# dm648_cslr_mcasp_001 register map
Vendor: Texas Instruments
Peripheral module from a debugger description file.
Registers are 32-bit, access not given, reset 0x0 unless marked. A register's access mark holds for its fields unless they carry their own. Offsets are as the file gives them; lines under a group give offsets from that group; [hi:lo] are bit positions; {n}, {i} and the like mark numbered series; 'fields as' and 'values as' point back to an identical list; <NAME> marks a mode.

## MCASP — This module provides an interface to program the MCASP (Multichannel Audio serial port) registers. These registers are memory mapped.
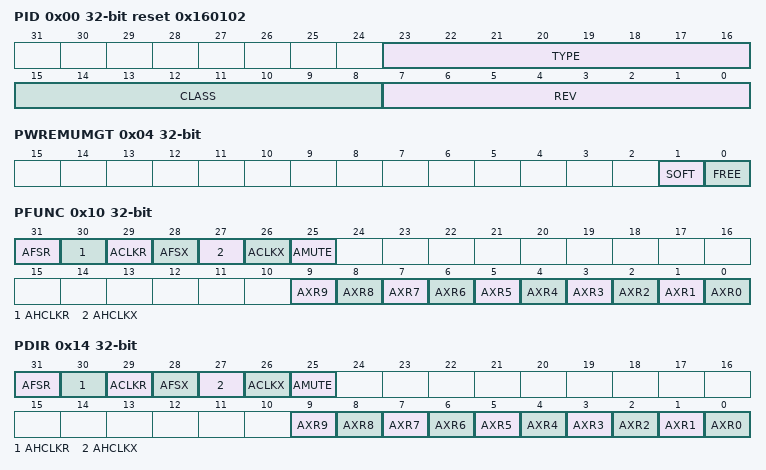
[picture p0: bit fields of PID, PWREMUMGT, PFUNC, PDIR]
0x00 PID reset 0x160102 — Peripheral Identification Register
  [23:16] TYPE ro — Identifies type of Peripheral
    22=MCASP (McASP is enabled)
  [15:8] CLASS ro — Identifies class of Peripheral
    1=SERPORT
  [7:0] REV ro — Identifies revision of Peripheral
0x04 PWREMUMGT — Power Down and Emulation ManagementRegister
  [1] SOFT rw — Implemented for compatibility with other peripherals
  [0] FREE rw — Functions during Emulation
    0=SOFT (SOFT bit takes effect)
0x10 PFUNC — Pin Function Register
  [all] fields
    0=MCASP; 1=GPIO
  [31] AFSR rw — AFSR pin
  [30] AHCLKR rw — AHCLKR pin
  [29] ACLKR rw — ACLKR pin
  [28] AFSX rw — AFSX pin
  [27] AHCLKX rw — AHCLKX pin
  [26] ACLKX rw — ACLKX pin
  [25] AMUTE rw — AMUTE pin
  [n] AXR{n} rw (n=0..9) — AXR{n} pin
0x14 PDIR — Pin Direction Register
  [all] fields
    0=IN; 1=OUT
  [31] AFSR rw — AFSR pin direction
  [30] AHCLKR rw — AHCLKR pin direction
  [29] ACLKR rw — ACLKR pin direction
  [28] AFSX rw — AHCLKX pin direction
  [27] AHCLKX rw — AFSX pin direction
  [26] ACLKX rw — ACLKX pin direction
  [25] AMUTE rw — AMUTE pin direction
  [n] AXR{n} rw (n=0..9) — AXR{n} pin direction
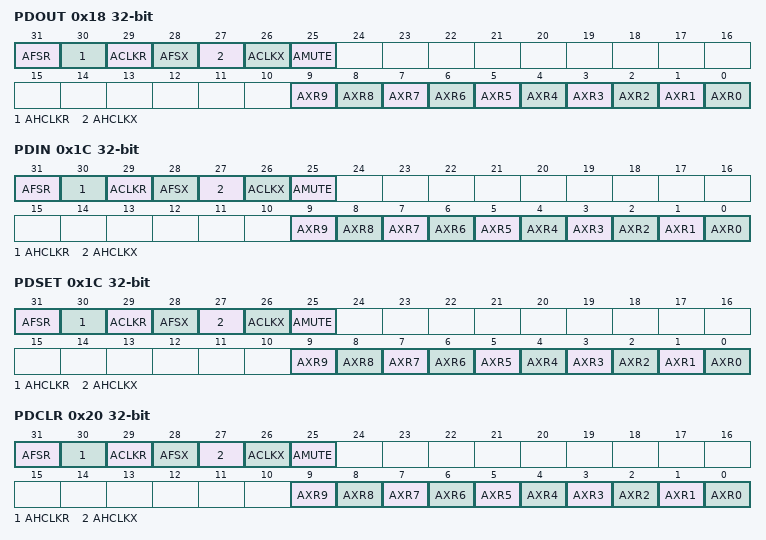
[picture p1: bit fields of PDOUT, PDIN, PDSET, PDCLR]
0x18 PDOUT — Pin Data Out Register
  [all] fields
    0=LOW; 1=HIGH
  [31] AFSR rw — AFSR pin value out
  [30] AHCLKR rw — AHCLKR pin value out
  [29] ACLKR rw — ACLKR pin value out
  [28] AFSX rw — AFSX pin value out
  [27] AHCLKX rw — AHCLKX pin value out
  [26] ACLKX rw — ACLKX pin value out
  [25] AMUTE rw — AMUTE pin value out
  [n] AXR{n} rw (n=0..9) — AXR{n} pin value out
0x1C PDIN — Pin Data In Register
  [all] fields
    1=SET
  [31] AFSR ro — AFSR pin input
  [30] AHCLKR ro — AHCLKR pin input
  [29] ACLKR ro — ACLKR pin input
  [28] AFSX ro — AFSX pin input
  [27] AHCLKX ro — AHCLKX pin input
  [26] ACLKX ro — ACLKX pin input
  [25] AMUTE ro — AMUTE pin input
  [n] AXR{n} ro (n=0..9) — AXR{n} pin input
0x1C PDSET — Pin Data Set Register (Alternate Write Address PDOUT)
  [all] fields
    1=SET
  [31] AFSR wo — Drive high on AFSR pin
  [30] AHCLKR wo — Drive high on AHCLKR pin
  [29] ACLKR wo — Drive high on ACLKR pin
  [28] AFSX wo — Drive high on AFSX pin
  [27] AHCLKX wo — Drive high on AHCLKX pin
  [26] ACLKX wo — Drive high on ACLKX pin
  [25] AMUTE wo — Drive high on AMUTE pin
  [n] AXR{n} wo (n=0..9) — Drive high on AXR{n} pin
0x20 PDCLR — Pin Data Clear Register
  [all] fields
    1=CLR
  [31] AFSR rw — Clears corresponding PDOUT bit to Low
  [30] AHCLKR rw — Clears corresponding PDOUT bit to Low
  [29] ACLKR rw — Clears corresponding PDOUT bit to Low
  [28] AFSX rw — Clears corresponding PDOUT bit to Low
  [27] AHCLKX rw — Clears corresponding PDOUT bit to Low
  [26] ACLKX rw — Clears corresponding PDOUT bit to Low
  [25] AMUTE rw — Clears corresponding PDOUT bit to Low
  [n] AXR{n} rw (n=0..9) — Clears corresponding PDOUT bit to Low
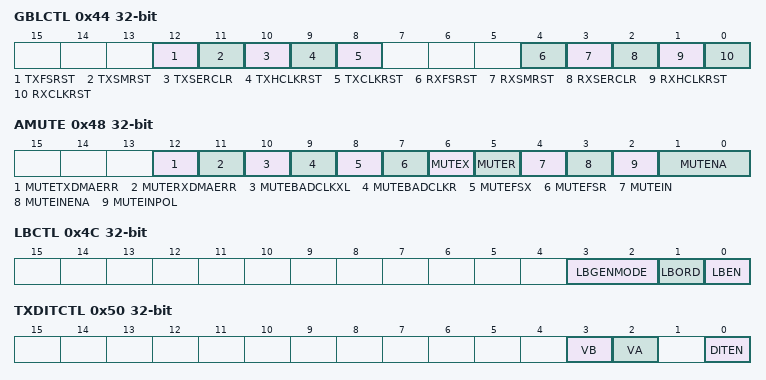
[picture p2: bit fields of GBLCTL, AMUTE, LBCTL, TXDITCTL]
0x44 GBLCTL — Global Control Register
  [12] TXFSRST rw — Transmit Frame Sync Generator Reset bit
    0=RESET; 1=ACTIVE
  [11] TXSMRST rw — Transmit State M/c Reset bit
    0=RESET; 1=ACTIVE
  [10] TXSERCLR rw — Transmit Serializers clear bit
    0=CLEAR; 1=ACTIVE
  [9] TXHCLKRST rw — Transmit High Freq Clock divider Reset bit
    0=RESET; 1=ACTIVE
  [8] TXCLKRST rw — Transmit Clock Divider reset bit
    0=RESET; 1=ACTIVE
  [4] RXFSRST rw — Receive Frame Sync Generator Reset bit
    0=RESET; 1=ACTIVE
  [3] RXSMRST rw — Receive State M/c Reset bit
    0=RESET; 1=ACTIVE
  [2] RXSERCLR rw — Receive Serializers clear bit
    0=CLEAR; 1=ACTIVE
  [1] RXHCLKRST rw — Receive High-Freq Clock Divider reset bit
    0=RESET; 1=ACTIVE
  [0] RXCLKRST rw — Receive Clock Divider is held Reset bit
    0=RESET; 1=ACTIVE
0x48 AMUTE — Mute Control register
  [12] MUTETXDMAERR rw — Transmit DMA Error
    0=DISABLE; 1=ENABLE
  [11] MUTERXDMAERR rw — Receive DMA Error
    0=DISABLE; 1=ENABLE
  [10] MUTEBADCLKXL rw — Transmit Clock Failure
    0=DISABLE; 1=ENABLE
  [9] MUTEBADCLKR rw — Receive Clock Failure
    0=DISABLE; 1=ENABLE
  [8] MUTEFSX rw — Unexpected Transmit Frame Sync
    0=DISABLE; 1=ENABLE
  [7] MUTEFSR rw — Unexpected Receive Frame Sync
    0=DISABLE; 1=ENABLE
  [6] MUTEX rw — Transmit Underrun Error
    0=DISABLE; 1=ENABLE
  [5] MUTER rw — Receive Overrun Error
    0=DISABLE; 1=ENABLE
  [4] MUTEIN ro — State of MUTE In Pin. 1 = Active.
  [3] MUTEINENA rw — Drive AMUTE active, when AMUTE pin is active
    0=DISABLE; 1=ENABLE
  [2] MUTEINPOL rw — AMUTEIN polarity select bit
    0=ACTHIGH; 1=ACTLOW
  [1:0] MUTENA rw — AMUTE pin enable bit
    0=DISABLE; 1=ERRHIGH; 2=ERRLOW
0x4C LBCTL — Loop Back Control Register
  [3:2] LBGENMODE rw — Loopback Generator Mode bits
    1=XMTCLK
  [1] LBORD rw — Loopback Order Odd Transmit to Even or vice versa
    0=XMTODD; 1=XMTEVEN
  [0] LBEN rw — Loopback Mode Enable Bit
    0=DISABLE; 1=ENABLE
0x50 TXDITCTL — Transmit DIT Mode Control Register
  [3] VB rw — Valid bit for Channel B
    0=ZERO; 1=ONE
  [2] VA rw — Valid bit for Channel A
    0=ZERO; 1=ONE
  [0] DITEN rw — DIT Transmit Enable bit
    0=TDM; 1=DIT
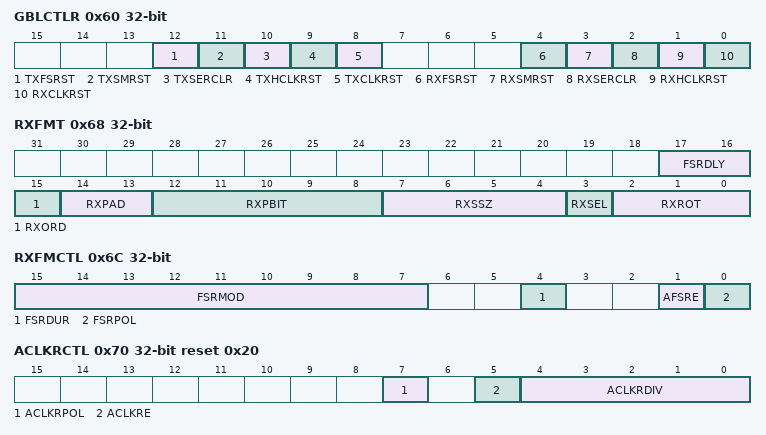
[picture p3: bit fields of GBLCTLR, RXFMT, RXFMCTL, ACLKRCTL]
0x60 GBLCTLR — Alias of GBLCTL - only receive bits
  [12] TXFSRST rw — Transmit Frame Sync Generator Reset Enable Bit
  [11] TXSMRST rw — Transmit State Machine Reset Enable Bit
  [10] TXSERCLR rw — Transmit Serializers Clear Enable Bit
  [9] TXHCLKRST rw — Transmit High-Freq Clock Divider Reset Enable Bit
  [8] TXCLKRST rw — Transmit Clock Divider Reset Enable Bit
  [4] RXFSRST rw — Receive Frame Sync Generator Reset Enable Bit
    0=RESET; 1=ACTIVE
  [3] RXSMRST rw — Receive State Machine Reset Enable Bit
    0=RESET; 1=ACTIVE
  [2] RXSERCLR rw — Receive Serializers Clear Enable Bit
    0=CLEAR; 1=ACTIVE
  [1] RXHCLKRST rw — Receive High-Freq Clock Divider Reset Enable Bit
    0=RESET; 1=ACTIVE
  [0] RXCLKRST rw — Receive Clock Divider Reset Enable Bit
    0=RESET; 1=ACTIVE
0x64 RXMASK rw — Receiver Format Unit Bit Mask Register
  [31:0] RXMASK — Corresponding bit of rcv data is not masked out
    0=USEMASK; 1=NOMASK
0x68 RXFMT — Receiver Bit Stream Format Register
  [17:16] FSRDLY rw — Receive Frame Sync Bit Delay
    0=0BIT; 1=1BIT; 2=2BIT
  [15] RXORD rw — Receive Serial Bit Stream Order
    0=LSBFIRST; 1=MSBFIRST
  [14:13] RXPAD rw — Pad value for extra bits in slot not belonging to word defined by RMASK
    0=ZERO; 1=ONE; 2=RPBIT
  [12:8] RXPBIT rw — Determines what to pad in slot
  [7:4] RXSSZ rw — Receive Slot size
  [3] RXSEL rw — Selects the VBUSP or the VBUS for the reads to come from
    0=fromVBUSP; 1=fromVBUS
  [2:0] RXROT rw — Right rotation value for receive rotate right format unit
    0=NONE; 1=4BITS; 2=8BITS; 3=12BITS; 4=16BITS; 5=20BITS; 6=24BITS; 7=28BITS
0x6C RXFMCTL — Receive Frame Sync Control Register
  [15:7] FSRMOD rw — Receive Frame Sync Mode Select bits
    0=BURST
  [4] FSRDUR rw — Receive Frame Sync Duration
    0=BIT; 1=WORD
  [1] AFSRE rw — Receive Frame Sync Generation Select bit
    0=EXTERNAL; 1=INTERNAL
  [0] FSRPOL rw — Receive Frame Sync Polarity Select bit
    0=ACTIVEHIGH; 1=ACTIVELOW
0x70 ACLKRCTL reset 0x20 — Receive Clock Control Register
  [7] ACLKRPOL rw — Receive Bit Stream Clock Polarity Select bit
    0=FALLING; 1=RISING
  [5] ACLKRE rw — Receive Clock Source bit
    0=EXTERNAL; 1=INTERNAL
  [4:0] ACLKRDIV rw — Receive Clock Divide from High Clock
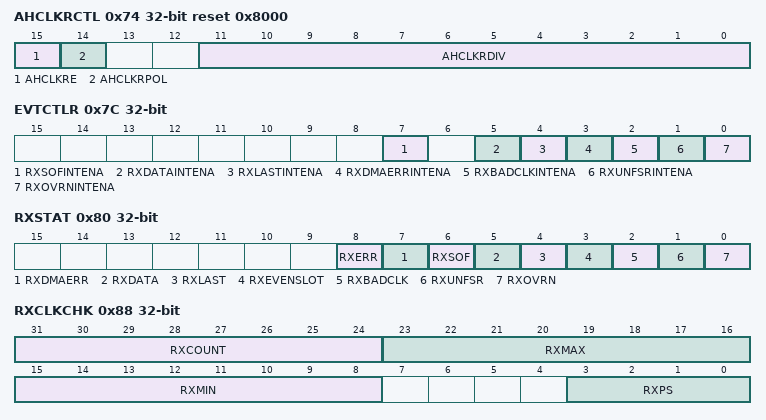
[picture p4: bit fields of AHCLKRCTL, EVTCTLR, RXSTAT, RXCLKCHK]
0x74 AHCLKRCTL reset 0x8000 — High Frequency Receive Clock Control Register
  [15] AHCLKRE rw — Receive High-Freq Clock Source Select bit
    0=EXTERNAL; 1=INTERNAL
  [14] AHCLKRPOL rw — Receive High-Freq Clock Polarity Select bit
    0=RISING; 1=FALLING
  [11:0] AHCLKRDIV rw — Receive Clock Divide Ratio from CPU
0x78 RXTDM rw — Receive TDM Slot 0-31 register description
  [31:0] RTDMS — Receive TDM Slot n is active/inactive
    0=INACTIVE; 1=ACTIVE
0x7C EVTCTLR — Receiver Interrupt Control Register
  [all] fields
    0=DISABLE; 1=ENABLE
  [7] RXSOFINTENA rw — Receive Start of Frame Interrupt Enable bit
  [5] RXDATAINTENA rw — Receive Data Ready Interrupt Enable bit
  [4] RXLASTINTENA rw — Receive Last Slot Interrupt Enable bit
  [3] RXDMAERRINTENA rw — Receive DMA Error Interrupt Enable bit
  [2] RXBADCLKINTENA rw — Receive Clock Failure Interrupt Enable bit
  [1] RXUNFSRINTENA rw — Receive Frame Sync Error Interrupt Enable bit
  [0] RXOVRNINTENA rw — Receive Overrun Error Interrupt Enable bit
0x80 RXSTAT — Receiver Status Register Description
  [8] RXERR rw — OR of (ROVRN | RSYNCERR | RCKFAIL | RDMAERR)
  [7] RXDMAERR rw — Receive DMA Bus Error
  [6] RXSOF rw — Receive Start of Frame Interrupt Bit
    0=NO; 1=YES
  [5] RXDATA rw — Receive Data Ready Interrupt bit
    0=NO; 1=YES
  [4] RXLAST rw — Receive Last Slot Interrupt bit
    0=NO; 1=YES
  [3] RXEVENSLOT — Returns the LSB of RTDMSLOT Counter (access N)
  [2] RXBADCLK rw — Receive Clock Failure Error bit
    0=NO; 1=YES
  [1] RXUNFSR rw — Receive Unexpected Frame Sync Error bit
    0=NO; 1=YES
  [0] RXOVRN rw — Receive Overrun Error bit
    0=NO; 1=YES
0x84 RXTDMSLOT — Current Receive TDM Slot
  [8:0] RXTDMSLOT ro — Receive TDM Slot Counter - Legal [0-383]
0x88 RXCLKCHK — Receive Clock Check Control Register
  [31:24] RXCOUNT ro — Count Value From Previous Measurement
  [23:16] RXMAX rw — Maximum Value for Clock Check counter
  [15:8] RXMIN rw — Minimum Value for Clock Check counter
  [3:0] RXPS rw — Receive Clock Check Prescalar value
    0=DIVBY1; 1=DIVBY2; 2=DIVBY4; 3=DIVBY8; 4=DIVBY16; 5=DIVBY32; 6=DIVBY64; 7=DIVBY128; 8=DIVBY256
0x8C REVTCTL — Receiver DMA event control
  [0] RDATDMA rw — Receive DMA event disable bit
    0=ENABLE; 1=DISABLE
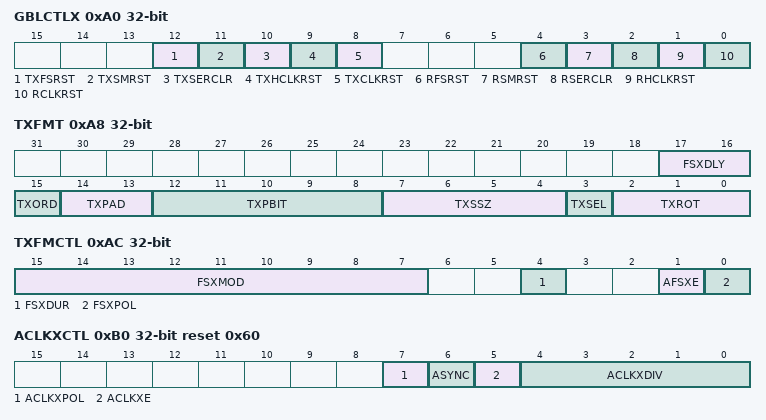
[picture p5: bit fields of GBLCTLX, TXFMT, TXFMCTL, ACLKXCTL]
0xA0 GBLCTLX — Alias of GBLCTL - only transmit bits
  [12] TXFSRST rw — Transmit Frame Sync Generator reset enable bit
    0=RESET; 1=ACTIVE
  [11] TXSMRST rw — Transmit State M/c reset enable bit
    0=RESET; 1=ACTIVE
  [10] TXSERCLR rw — Transmit Serializer clear enable bit
    0=CLEAR; 1=ACTIVE
  [9] TXHCLKRST rw — Transmit High-Freq Clock Divider reset enable bit
    0=RESET; 1=ACTIVE
  [8] TXCLKRST rw — Transmit Clock Divider reset enable bit
    0=RESET; 1=ACTIVE
  [4] RFSRST ro — Receive Frame Sync Generator reset enable bit
  [3] RSMRST ro — Receive State M/c reset enable bit
  [2] RSERCLR ro — Receive Serializer clear enable bit
  [1] RHCLKRST ro — Receive High-Freq Clock Divider reset enable bit
  [0] RCLKRST ro — Receive Clock Divider reset enable bit
0xA4 TXMASK rw — Transmit Format Unit Bit Mask Register
  [31:0] TXMASK — Corresponding bit of xmt data is not masked out
    0=USEMASK; 1=NOMASK
0xA8 TXFMT — Transmit Bit Stream Format Register
  [17:16] FSXDLY rw — Transmit Frame Sync bit delay bits
    0=0BIT; 1=1BIT; 2=2BIT
  [15] TXORD rw — Transmit Serial Bit Stream Order
    0=LSBFIRST; 1=MSBFIRST
  [14:13] TXPAD rw — Pad value for extra bits in slot not belonging to word defined by XMASK
    0=ZERO; 1=ONE; 2=TXPBIT
  [12:8] TXPBIT rw — Determines what to pad in slot
  [7:4] TXSSZ rw — Transmit Slot Size
  [3] TXSEL rw — Selects if VBUSP or VBUS originates the writes
    0=fromVBUSP; 1=fromVBUS
  [2:0] TXROT rw — Right rotation value for Transmit rotate right format unit
    values as RXFMT.RXROT
0xAC TXFMCTL — Transmit Frame Sync Control Register
  [15:7] FSXMOD rw — Transmit Frame Sync Mode Select bits
    0=BURST
  [4] FSXDUR rw — Transmit Frame Sync Width Select bit
    0=BIT; 1=WORD
  [1] AFSXE rw — Transmit Frame Sync Generation Select bit
    0=EXTERNAL; 1=INTERNAL
  [0] FSXPOL rw — Transmit Frame Sync Polarity Select bit
    0=ACTIVEHIGH; 1=ACTIVELOW
0xB0 ACLKXCTL reset 0x60 — Transmit Clock Control Register
  [7] ACLKXPOL rw — Transmit Bitstream Clock Polarity Select bit
    0=RISING; 1=FALLING
  [6] ASYNC rw — Transmit/Receive Operation Async enable bit
    0=SYNC; 1=ASYNC
  [5] ACLKXE rw — Transmit Clock Source Select bit
    0=EXTERNAL; 1=INTERNAL
  [4:0] ACLKXDIV rw — Transmit Clock Divide from High Clock
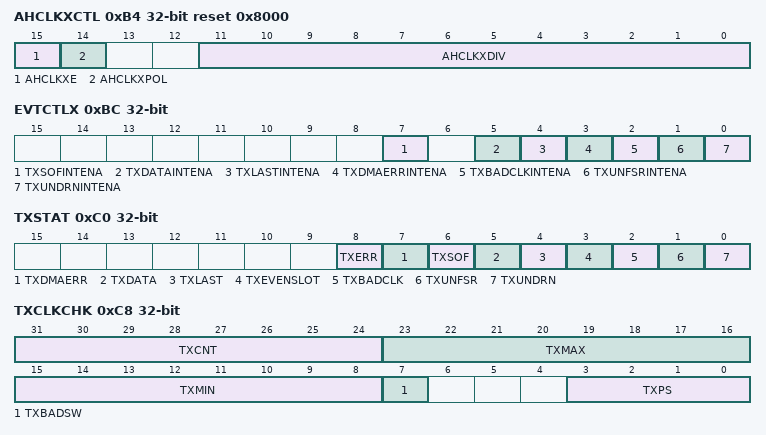
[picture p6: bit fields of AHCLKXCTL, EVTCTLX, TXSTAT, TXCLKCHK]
0xB4 AHCLKXCTL reset 0x8000 — High Frequency Transmit Clock Control Register
  [15] AHCLKXE rw — Trasnmit High-Freq Clock Source Select bit
    0=EXTERNAL; 1=INTERNAL
  [14] AHCLKXPOL rw — Trasnmit High-Freq Clock Polarity Select bit
    0=RISING; 1=FALLING
  [11:0] AHCLKXDIV rw — Transmit Clock Divide Ratio from CPU
0xB8 TXTDM rw — Transmit TDM Slot 0-31 register description
  [31:0] XTDMS — Transmit TDM slot n is active/inactive
    0=INACTIVE; 1=ACTIVE
0xBC EVTCTLX — Transmit Interrupt Control Register
  [all] fields
    0=DISABLE; 1=ENABLE
  [7] TXSOFINTENA rw — Transmit Start of Frame Interrupt Enable bit
  [5] TXDATAINTENA rw — Transmit Data Ready Interrupt Enable bit
  [4] TXLASTINTENA rw — Transmit Last Slot Interrupt Enable bit
  [3] TXDMAERRINTENA rw — Transmit DMA Error Interrupt Enable bit
  [2] TXBADCLKINTENA rw — Transmit Clock Failure Interupt Enable bit
  [1] TXUNFSRINTENA rw — Transmit Unexpected Frame Interrupt Enable bit
  [0] TXUNDRNINTENA rw — Transmit Underrun Error Interrupt Enable bit
0xC0 TXSTAT — Transmit Status Register Description
  [8] TXERR rw — OR of (TXOVRN | TXUNFSR | TXBADCLK | TXDMAERR)
  [7] TXDMAERR rw — Transmit DMA Bus Error
  [6] TXSOF rw — Transmit Start of Frame bit
    0=NO; 1=YES
  [5] TXDATA rw — Transmit Data Ready bit
    0=NO; 1=YES
  [4] TXLAST rw — Transmit Last Slot bit
    0=NO; 1=YES
  [3] TXEVENSLOT ro — Returns the LSB of TXTDMSLOT Counter
  [2] TXBADCLK rw — Transmit Clock Failure Error bit
    0=NO; 1=YES
  [1] TXUNFSR rw — Transmit Unexpected Frame Sync Error bit
    0=NO; 1=YES
  [0] TXUNDRN rw — Transmit Underrun Error bit
    0=NO; 1=YES
0xC4 TXTDMSLOT (reset mask 0xFFFFFE00) — Current Transmit TDM Slot
  [8:0] TXTDMSLOT ro — Transmit TDM Slot Counter - Legal [0-383] ( 0 After reset)
0xC8 TXCLKCHK — Transmit Clock Check Control Register
  [31:24] TXCNT ro — Count Value From Previous Measurement
  [23:16] TXMAX rw — Maximum Value for Clock Check counter
  [15:8] TXMIN rw — Minimum Value for Clock Check counter
  [7] TXBADSW rw — Transmit Clock Failure detect autoswitch enable bit
    0=DISABLE; 1=ENABLE
  [3:0] TXPS rw — Transmit Clock Check Prescalar value
    values as RXCLKCHK.RXPS
0xCC XEVTCTL — Transmit DMA event control
  [0] TXDATADMADIS rw — Transmit DMA event disable bit
    0=ENABLE; 1=DISABLE
{0x100+4i} DITCSRA{i} rw (i=0..5) — DIT Channel Status Register A{i}
  [31:0] DITCSRA{i} — Channel Status Data
{0x118+4i} DITCSRB{i} rw (i=0..5) — DIT Channel Status Register B{i}
  [31:0] DITCSRB{i} — Channel Status Data
{0x130+4i} DITUDRA{i} rw (i=0..5) — DIT User Data Register A{i}
  [31:0] DITUDRA{i} — User Data
{0x148+4i} DITUDRB{i} rw (i=0..5) — DIT User Data Register B{i}
  [31:0] DITUDRB{i} — User Data
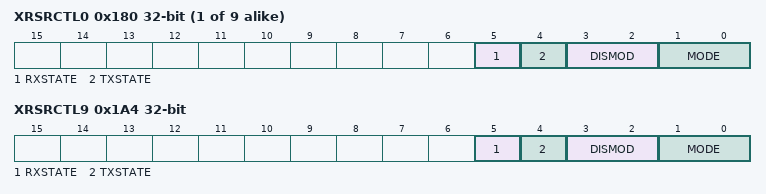
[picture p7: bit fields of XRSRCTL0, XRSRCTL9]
{0x180+4i} XRSRCTL{i} (i=0..8) — Serializer Control Register {i}
  [5] RXSTATE ro — Reflects the current Receive buffer state
  [4] TXSTATE ro — Reflects the current Transmit buffer state
  [3:2] DISMOD rw — Serializer pin Drive Mode bit, when Transmitting in inactive slots
    0=3STATE; 2=LOW; 3=HIGH
  [1:0] MODE rw — Serializer mode bit
    0=INACTIVE; 1=XMT; 2=RCV
0x1A4 XRSRCTL9 — Serializer Control Register 9
  [5] RXSTATE ro — Reflects the current Receive buffer state
  [4] TXSTATE ro — Reflects the current Transmit buffer state
  [3:2] DISMOD rw — Serializer pin Drive Mode bit, when Transmitting in inactive slots
    0=3STATE; 2=LOW; 3=HIGH
  [1:0] MODE rw — Serializer mode bit
    0=INACTIVE; 1=XMT; 2=RCV; 2=RCV
{0x200+4i} TXBUF{i} wo (i=0..9) — Transmit Buffer Register {i}
  [31:0] TXBUF{i} — Data registers to which a 32 bit data is written into
{0x280+4i} RXBUF{i} ro (i=0..9) — Receive Buffer Register {i}
  [31:0] RXBUF{i} — Data registers to which a 32 bit data is read from
